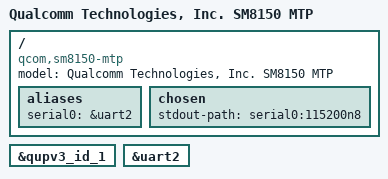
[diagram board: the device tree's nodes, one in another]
// SPDX-License-Identifier: BSD-3-Clause
// Copyright (c) 2017-2019, The Linux Foundation. All rights reserved.
// Copyright (c) 2019, Linaro Limited

/dts-v1/;

#include "sm8150.dtsi"

/ {
	model = "Qualcomm Technologies, Inc. SM8150 MTP";
	compatible = "qcom,sm8150-mtp";

	aliases {
		serial0 = &uart2;
	};

	chosen {
		stdout-path = "serial0:115200n8";
	};
};

&qupv3_id_1 {
	status = "okay";
};

&uart2 {
	status = "okay";
};
